# iostr711 register map
Registers from a debugger description file.
Registers are 16-bit, access not given, no defined reset value unless marked. A register's access mark holds for its fields unless they carry their own. Addresses are absolute; registers are grouped by the start of their names; lines under a group give offsets from that group; [hi:lo] are bit positions; {n}, {i} and the like mark numbered series; 'fields as' and 'values as' point back to an identical list; <NAME> marks a mode.

## FLASH
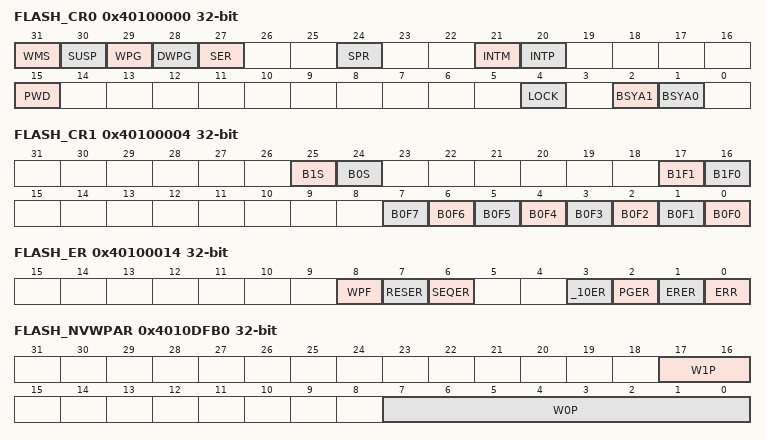
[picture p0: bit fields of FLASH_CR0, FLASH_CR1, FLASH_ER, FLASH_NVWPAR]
0x40100000 FLASH_CR0 32-bit
  [31] WMS, [30] SUSP, [29] WPG, [28] DWPG, [27] SER, [24] SPR, [21] INTM, [20] INTP, [15] PWD, [4] LOCK, [2] BSYA1, [1] BSYA0
0x40100004 FLASH_CR1 32-bit
  [25] B1S, [24] B0S, [17] B1F1, [16] B1F0, [n] B0F{n} (n=0..7)
0x40100008 FLASH_DR0 32-bit
0x4010000C FLASH_DR1 32-bit
0x40100010 FLASH_AR 32-bit
  [20:0] ADD
0x40100014 FLASH_ER 32-bit
  [8] WPF, [7] RESER, [6] SEQER, [3] _10ER, [2] PGER, [1] ERER, [0] ERR
0x4010DFB0 FLASH_NVWPAR 32-bit
  [17:16] W1P, [7:0] W0P
0x4010DFB8 FLASH_NVAPR0 32-bit
  [1] DBGP
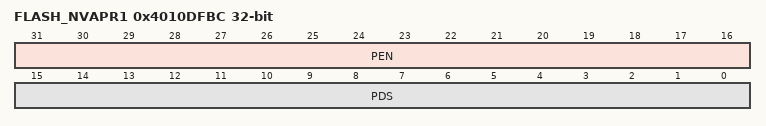
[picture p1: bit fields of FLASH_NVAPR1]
0x4010DFBC FLASH_NVAPR1 32-bit
  [31:16] PEN, [15:0] PDS

## RCCU
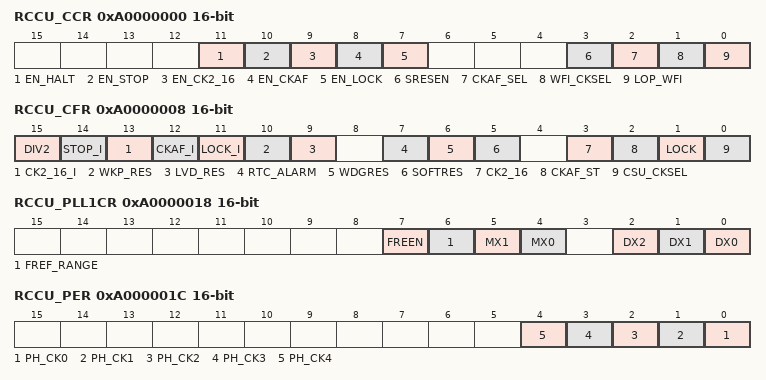
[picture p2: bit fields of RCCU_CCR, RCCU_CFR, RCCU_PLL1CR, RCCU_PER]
0xA0000000 RCCU_CCR
  [11] EN_HALT, [10] EN_STOP, [9] EN_CK2_16, [8] EN_CKAF, [7] EN_LOCK, [3] SRESEN, [2] CKAF_SEL, [1] WFI_CKSEL, [0] LOP_WFI
0xA0000008 RCCU_CFR
  [15] DIV2, [14] STOP_I, [13] CK2_16_I, [12] CKAF_I, [11] LOCK_I, [10] WKP_RES, [9] LVD_RES, [7] RTC_ALARM, [6] WDGRES, [5] SOFTRES, [3] CK2_16, [2] CKAF_ST, [1] LOCK, [0] CSU_CKSEL
0xA0000018 RCCU_PLL1CR
  [7] FREEN, [6] FREF_RANGE, [5] MX1, [4] MX0, [2] DX2, [1] DX1, [0] DX0
0xA000001C RCCU_PER
  [n] PH_CK{n} (n=0..4)
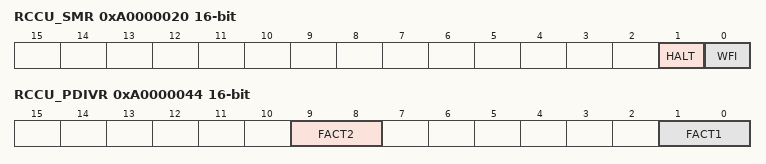
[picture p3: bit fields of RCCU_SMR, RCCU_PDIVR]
0xA0000020 RCCU_SMR
  [1] HALT, [0] WFI
0xA0000040 RCCU_MDIVR
  [1:0] FACT
0xA0000044 RCCU_PDIVR
  [9:8] FACT2, [1:0] FACT1

## PCU
0xA0000048 PCU_PRSTR
  [2] EMIRST
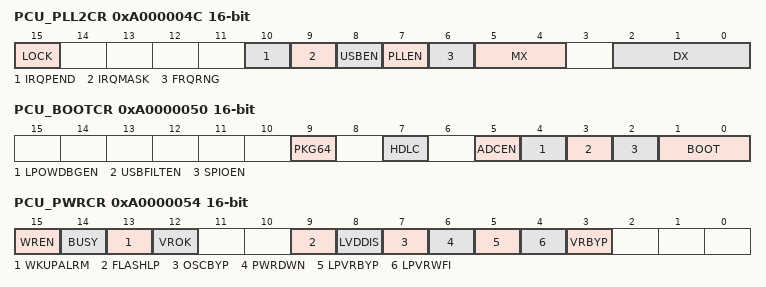
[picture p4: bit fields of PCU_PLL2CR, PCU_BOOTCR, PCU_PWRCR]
0xA000004C PCU_PLL2CR
  [15] LOCK, [10] IRQPEND, [9] IRQMASK, [8] USBEN, [7] PLLEN, [6] FRQRNG, [5:4] MX, [2:0] DX
0xA0000050 PCU_BOOTCR
  [9] PKG64, [7] HDLC, [5] ADCEN, [4] LPOWDBGEN, [3] USBFILTEN, [2] SPIOEN, [1:0] BOOT
0xA0000054 PCU_PWRCR
  [15] WREN, [14] BUSY, [13] WKUPALRM, [12] VROK, [9] FLASHLP, [8] LVDDIS, [7] OSCBYP, [6] PWRDWN, [5] LPVRBYP, [4] LPVRWFI, [3] VRBYP

## IOPORT0
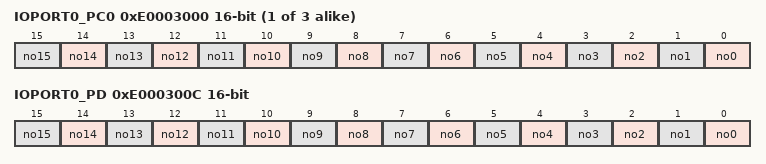
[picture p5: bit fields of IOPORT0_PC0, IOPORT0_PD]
{0xE0003000+4i} IOPORT0_PC{i} (i=0..2)
  [n] no{n} (n=0..15)
0xE000300C IOPORT0_PD
  [n] no{n} (n=0..15)

## IOPORT1
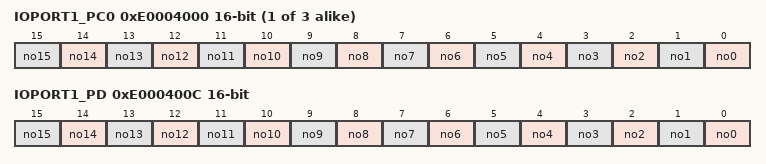
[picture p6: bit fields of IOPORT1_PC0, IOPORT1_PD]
{0xE0004000+4i} IOPORT1_PC{i} (i=0..2)
  [n] no{n} (n=0..15)
0xE000400C IOPORT1_PD
  [n] no{n} (n=0..15)

## EIC
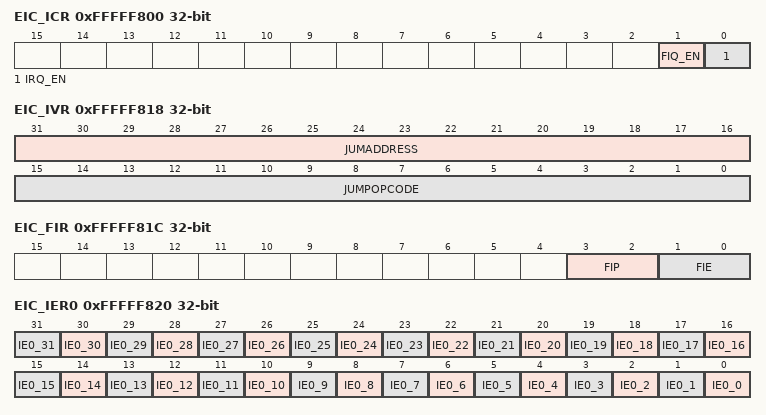
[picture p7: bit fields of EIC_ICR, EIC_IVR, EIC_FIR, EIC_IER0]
0xFFFFF800 EIC_ICR 32-bit
  [1] FIQ_EN, [0] IRQ_EN
0xFFFFF804 EIC_CICR 32-bit
  [4:0] CIC
0xFFFFF808 EIC_CIPR 32-bit
  [3:0] CIP
0xFFFFF818 EIC_IVR 32-bit
  [31:16] JUMADDRESS, [15:0] JUMPOPCODE
0xFFFFF81C EIC_FIR 32-bit
  [3:2] FIP, [1:0] FIE
0xFFFFF820 EIC_IER0 32-bit
  [n] IE0_{n} (n=0..31)
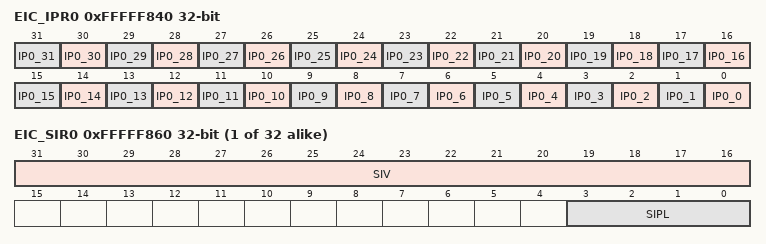
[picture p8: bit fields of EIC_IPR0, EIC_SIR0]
0xFFFFF840 EIC_IPR0 32-bit
  [n] IP0_{n} (n=0..31)
{0xFFFFF860+4i} EIC_SIR{i} 32-bit (i=0..31)
  [31:16] SIV, [3:0] SIPL

## XTI
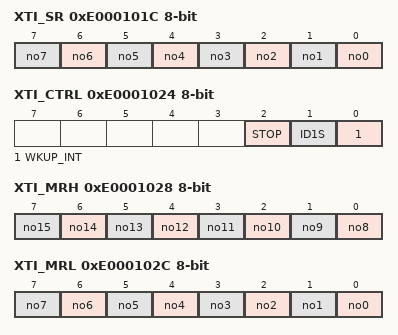
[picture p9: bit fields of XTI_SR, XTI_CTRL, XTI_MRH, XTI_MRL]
0xE000101C XTI_SR 8-bit
  [n] no{n} (n=0..7)
0xE0001024 XTI_CTRL 8-bit
  [2] STOP, [1] ID1S, [0] WKUP_INT
0xE0001028 XTI_MRH 8-bit
  [n-8] no{n} (n=8..15)
0xE000102C XTI_MRL 8-bit
  [n] no{n} (n=0..7)
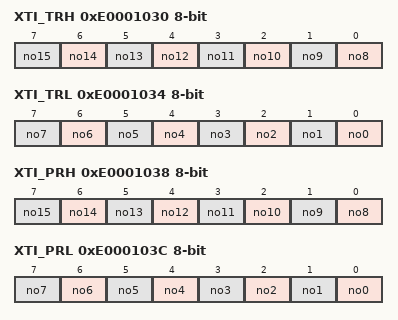
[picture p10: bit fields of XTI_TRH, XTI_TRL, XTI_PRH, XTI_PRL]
0xE0001030 XTI_TRH 8-bit
  [n-8] no{n} (n=8..15)
0xE0001034 XTI_TRL 8-bit
  [n] no{n} (n=0..7)
0xE0001038 XTI_PRH 8-bit
  [n-8] no{n} (n=8..15)
0xE000103C XTI_PRL 8-bit
  [n] no{n} (n=0..7)

## RTC
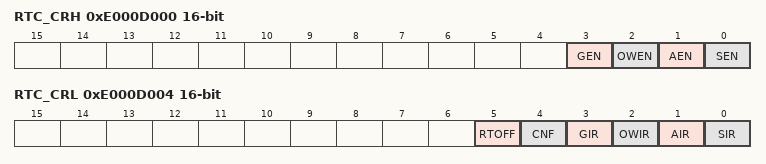
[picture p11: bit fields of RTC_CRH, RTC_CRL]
0xE000D000 RTC_CRH
  [3] GEN, [2] OWEN, [1] AEN, [0] SEN
0xE000D004 RTC_CRL
  [5] RTOFF, [4] CNF, [3] GIR, [2] OWIR, [1] AIR, [0] SIR
0xE000D008 RTC_PRLH
  [3:0] PRSL
0xE000D00C RTC_PRLL
0xE000D010 RTC_DIVH
  [3:0] RTCDIV
0xE000D014 RTC_DIVL
0xE000D018 RTC_CNTH
0xE000D01C RTC_CNTL
0xE000D020 RTC_ALRH
0xE000D024 RTC_ALRL
